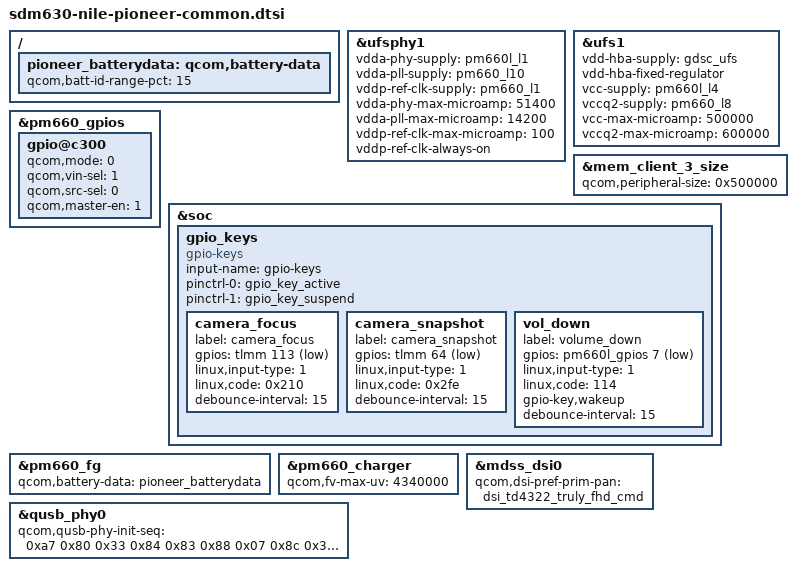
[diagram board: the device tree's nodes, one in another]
/* Copyright (c) 2017, The Linux Foundation. All rights reserved.
 *
 * This program is free software; you can redistribute it and/or modify
 * it under the terms of the GNU General Public License version 2 and
 * only version 2 as published by the Free Software Foundation.
 *
 * This program is distributed in the hope that it will be useful,
 * but WITHOUT ANY WARRANTY; without even the implied warranty of
 * MERCHANTABILITY or FITNESS FOR A PARTICULAR PURPOSE.  See the
 * GNU General Public License for more details.
 */

/ {
	pioneer_batterydata: qcom,battery-data {
		qcom,batt-id-range-pct = <15>;
		#include "fg-gen3-batterydata-tdk-3200mah.dtsi"
		#include "fg-gen3-batterydata-somc-3200mah.dtsi"
	};
};

&ufsphy1 {
	vdda-phy-supply = <&pm660l_l1>;
	vdda-pll-supply = <&pm660_l10>;
	vddp-ref-clk-supply = <&pm660_l1>;
	vdda-phy-max-microamp = <51400>;
	vdda-pll-max-microamp = <14200>;
	vddp-ref-clk-max-microamp = <100>;
	vddp-ref-clk-always-on;
	status = "ok";
};

&ufs1 {
	vdd-hba-supply = <&gdsc_ufs>;
	vdd-hba-fixed-regulator;
	vcc-supply = <&pm660l_l4>;
	vccq2-supply = <&pm660_l8>;
	vcc-max-microamp = <500000>;
	vccq2-max-microamp = <600000>;
	status = "ok";
};

&pm660_gpios {
	/* GPIO 4 (NFC_CLK_REQ) */
	gpio@c300 {
		qcom,mode = <0>;
		qcom,vin-sel = <1>;
		qcom,src-sel = <0>;
		qcom,master-en = <1>;
		status = "okay";
	};
};

&mem_client_3_size {
	qcom,peripheral-size = <0x500000>;
};

&soc {
	gpio_keys {
		status = "okay";
		compatible = "gpio-keys";
		input-name = "gpio-keys";
		pinctrl-names = "tlmm_gpio_key_active","tlmm_gpio_key_suspend";
		pinctrl-0 = <&gpio_key_active>;
		pinctrl-1 = <&gpio_key_suspend>;

		camera_focus {
			label = "camera_focus";
			gpios = <&tlmm 113 0x1>;
			linux,input-type = <1>;
			linux,code = <0x210>;
			debounce-interval = <15>;
		};

		camera_snapshot {
			label = "camera_snapshot";
			gpios = <&tlmm 64 0x1>;
			linux,input-type = <1>;
			linux,code = <0x2fe>;
			debounce-interval = <15>;
		};

		vol_down {
			label = "volume_down";
			gpios = <&pm660l_gpios 7 0x1>;
			linux,input-type = <1>;
			linux,code = <114>;
			gpio-key,wakeup;
			debounce-interval = <15>;
		};
	};
};

&pm660_fg {
	qcom,battery-data = <&pioneer_batterydata>;
};

&pm660_charger {
	qcom,fv-max-uv = <4340000>;
};

&mdss_dsi0 {
	qcom,dsi-pref-prim-pan = <&dsi_td4322_truly_fhd_cmd>;
};

&qusb_phy0 {
	qcom,qusb-phy-init-seq = <0xa7 0x80
				  0x33 0x84
				  0x83 0x88
				  0x07 0x8c
				  0x30 0x08
				  0x79 0x0c
				  0x21 0x10
				  0x14 0x9c
				  0x9f 0x1c
				  0x00 0x18>;
};

